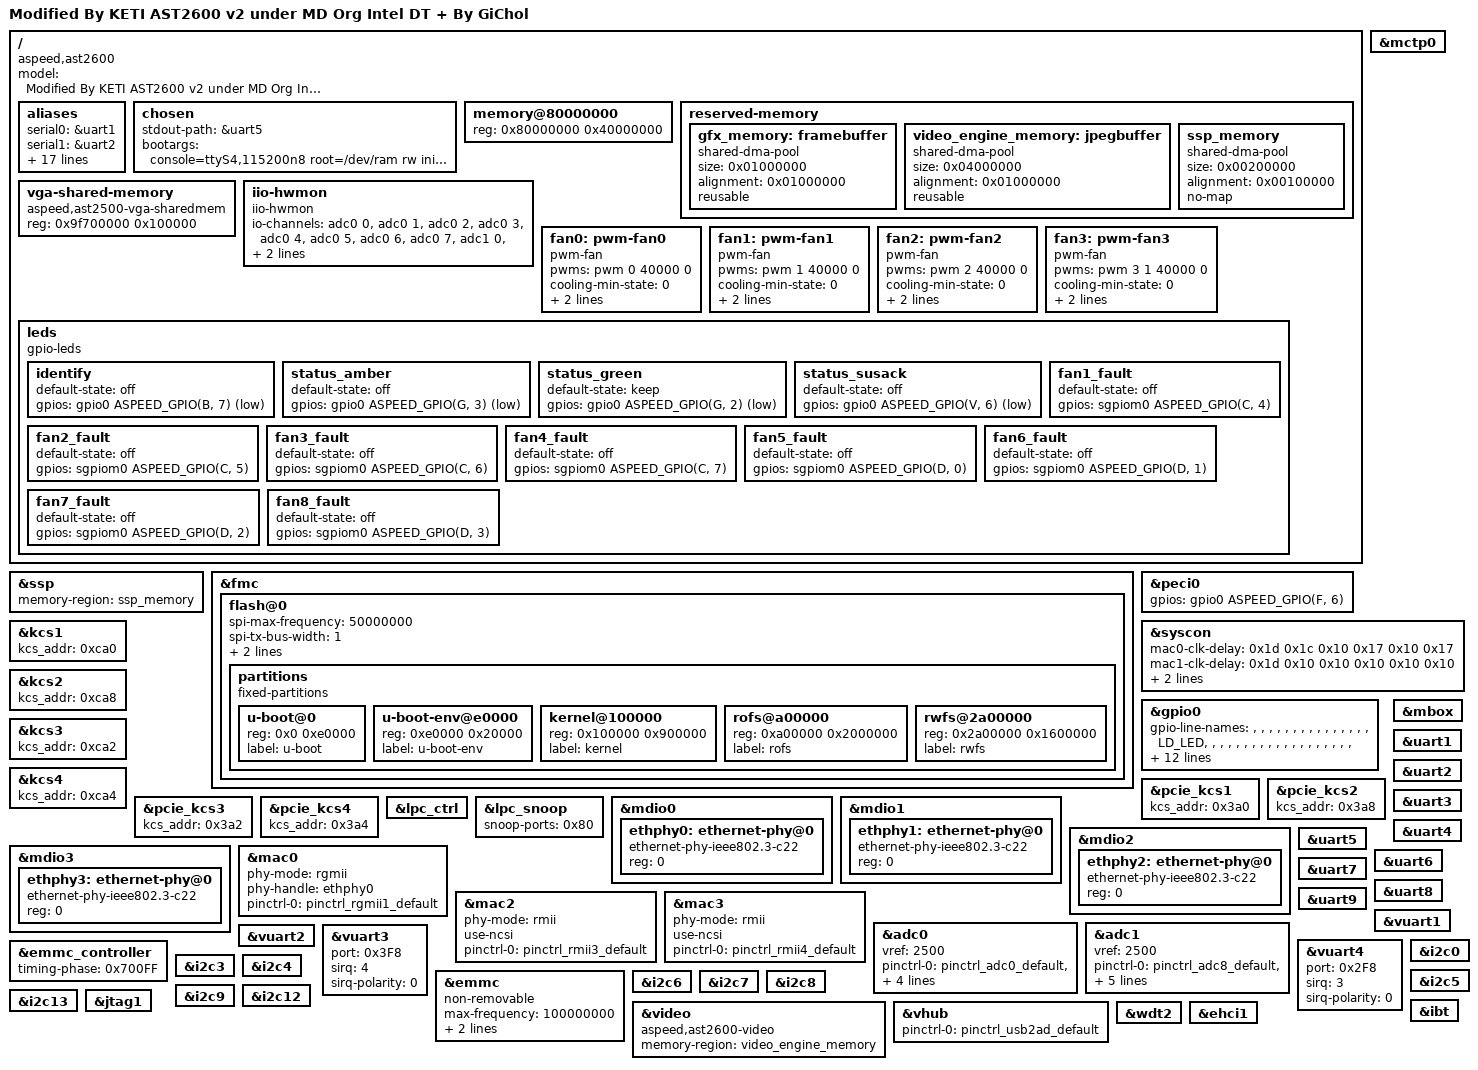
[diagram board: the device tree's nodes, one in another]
// SPDX-License-Identifier: GPL-2.0+
/dts-v1/;

#include "aspeed-g6.dtsi"
#include <dt-bindings/gpio/aspeed-gpio.h>
#include <dt-bindings/i2c/i2c.h>

/ {
   model = "Modified By KETI AST2600 v2 under MD Org Intel DT + By GiChol";
   compatible = "aspeed,ast2600";

   aliases {
      serial0 = &uart1;
                serial1 = &uart2;
                serial2 = &uart3;
                serial3 = &uart4;
                serial4 = &uart5;
                serial5 = &uart6;
                serial6 = &uart7;
                serial7 = &uart8;
                serial8 = &uart9;
                serial9 = &uart10;
                serial10 = &uart11;
                serial11 = &uart12;
                serial12 = &uart13;
                serial13 = &vuart1;
                serial14 = &vuart2;
                serial15 = &vuart3;
                serial16 = &vuart4;
                mctp0 = &mctp0;
                mctp1 = &mctp1;
   };

   chosen {
      stdout-path = &uart5;
      bootargs = "console=ttyS4,115200n8 root=/dev/ram rw init=/linuxrc earlyprintk";
   };

   memory@80000000 {
      device_type = "memory";
      reg = <0x80000000 0x40000000>;
   };

   reserved-memory {
      #address-cells = <1>;
      #size-cells = <1>;
      ranges;

      gfx_memory: framebuffer {
         size = <0x01000000>;
         alignment = <0x01000000>;
         compatible = "shared-dma-pool";
         reusable;
      };

      video_engine_memory: jpegbuffer {
         size = <0x04000000>;
         alignment = <0x01000000>;
         compatible = "shared-dma-pool";
         reusable;
      };
      ssp_memory: ssp_memory {
         size = <0x00200000>;
         alignment = <0x00100000>;
         compatible = "shared-dma-pool";
         no-map;
      };
   };

   vga-shared-memory {
      compatible = "aspeed,ast2500-vga-sharedmem";
      reg = <0x9f700000 0x100000>;
   };

   iio-hwmon {
      compatible = "iio-hwmon";
      io-channels = <&adc0 0>, <&adc0 1>, <&adc0 2>, <&adc0 3>,
         <&adc0 4>, <&adc0 5>, <&adc0 6>, <&adc0 7>,
         <&adc1 0>, <&adc1 1>, <&adc1 2>, <&adc1 3>,
         <&adc1 4>, <&adc1 5>, <&adc1 6>, <&adc1 7>;
   };
        fan0: pwm-fan0 {
                compatible = "pwm-fan";
                pwms = <&pwm 0 40000 0>;        /* Target freq:25 kHz */
                cooling-min-state = <0>;
                cooling-max-state = <3>;
                #cooling-cells = <2>;
                cooling-levels = <0 25 128 255>;
        };

        fan1: pwm-fan1 {
                compatible = "pwm-fan";
                pwms = <&pwm 1 40000 0>;        /* Target freq:25 kHz */
                cooling-min-state = <0>;
                cooling-max-state = <3>;
                #cooling-cells = <2>;
                cooling-levels = <0 15 128 255>;
        };

        fan2: pwm-fan2 {
                compatible = "pwm-fan";
                pwms = <&pwm 2 40000 0>;        /* Target freq:25 kHz */
                cooling-min-state = <0>;
                cooling-max-state = <3>;
                #cooling-cells = <2>;
                cooling-levels = <0 15 128 255>;
        };

        fan3: pwm-fan3 {
                compatible = "pwm-fan";
                pwms = <&pwm 3 1 40000 0>;        /* Target freq:25 kHz */
                cooling-min-state = <0>;
                cooling-max-state = <3>;
                #cooling-cells = <2>;
                cooling-levels = <0 15 128 255>;
        };

        leds {
                compatible = "gpio-leds";

                identify {
                        default-state = "off";
                        gpios = <&gpio0 ASPEED_GPIO(B, 7) GPIO_ACTIVE_LOW>;
                };

                status_amber {
                        default-state = "off";
                        gpios = <&gpio0 ASPEED_GPIO(G, 3) GPIO_ACTIVE_LOW>;
                };

                status_green {
                        default-state = "keep";
                        gpios = <&gpio0 ASPEED_GPIO(G, 2) GPIO_ACTIVE_LOW>;
                };

                status_susack {
                        default-state = "off";
                        gpios = <&gpio0 ASPEED_GPIO(V, 6) GPIO_ACTIVE_LOW>;
                };

                fan1_fault {
                        default-state = "off";
                        gpios = <&sgpiom0 ASPEED_GPIO(C, 4) GPIO_ACTIVE_HIGH>;
                };

                fan2_fault {
                        default-state = "off";
                        gpios = <&sgpiom0 ASPEED_GPIO(C, 5) GPIO_ACTIVE_HIGH>;
                };

                fan3_fault {
                        default-state = "off";
                        gpios = <&sgpiom0 ASPEED_GPIO(C, 6) GPIO_ACTIVE_HIGH>;
                };

                fan4_fault {
                        default-state = "off";
                        gpios = <&sgpiom0 ASPEED_GPIO(C, 7) GPIO_ACTIVE_HIGH>;
                };

                fan5_fault {
                        default-state = "off";
                        gpios = <&sgpiom0 ASPEED_GPIO(D, 0) GPIO_ACTIVE_HIGH>;
                };

                fan6_fault {
                        default-state = "off";
                        gpios = <&sgpiom0 ASPEED_GPIO(D, 1) GPIO_ACTIVE_HIGH>;
                };

                fan7_fault {
                        default-state = "off";
                        gpios = <&sgpiom0 ASPEED_GPIO(D, 2) GPIO_ACTIVE_HIGH>;
                };

                fan8_fault {
                        default-state = "off";
                        gpios = <&sgpiom0 ASPEED_GPIO(D, 3) GPIO_ACTIVE_HIGH>;
                };
        };
};

&ssp {
      memory-region = <&ssp_memory>;
};

&fmc {
   status = "okay";
   flash@0 {
      status = "okay";
      spi-max-frequency = <50000000>;
      spi-tx-bus-width = <1>;
      spi-rx-bus-width = <4>;
      m25p,fast-read;
      partitions {
         compatible = "fixed-partitions";
         #address-cells = <1>;
         #size-cells = <1>;

         u-boot@0 {
            reg = <0x0 0xe0000>;
            label = "u-boot";
         };

         u-boot-env@e0000 {
            reg = <0xe0000 0x20000>; // 128KB
            label = "u-boot-env";
         };

         kernel@100000 {
            reg = <0x100000 0x900000>; // 9MB
            label = "kernel";
         };

         rofs@a00000 {
            reg = <0xa00000 0x2000000>; // 32MB
            label = "rofs";
         };

         rwfs@2a00000 {
            reg = <0x2a00000 0x1600000>; // 22MB
            label = "rwfs";
         };
      };
   };
};
#if 0
&espi_ctrl {
   status = "okay";
   perif,memcyc-enable;
   perif,memcyc-src-addr = <0x98000000>;
   perif,memcyc-size = <0x10000>;
   perif,dma-mode;

   oob,dma-mode;
   oob,dma-tx-desc-num = <0x2>;
   oob,dma-rx-desc-num = <0x8>;

   flash,dma-mode;
   flash,safs-mode = <0x2>;
};
#endif

&mctp0 {
   status = "okay";
};

&peci0 {
   status = "okay";
   gpios = <&gpio0 ASPEED_GPIO(F, 6) 0>;
};

&syscon {
   mac0-clk-delay = <0x1d 0x1c
           0x10 0x17
           0x10 0x17>;
   mac1-clk-delay = <0x1d 0x10
           0x10 0x10
           0x10 0x10>;
   mac2-clk-delay = <0x0a 0x04
           0x08 0x04
           0x08 0x04>;
   mac3-clk-delay = <0x0a 0x04
           0x08 0x04
           0x08 0x04>;
};

&gpio0 {
        //pinctrl-names = "default";
        //pinctrl-0 = <&pinctrl_gpioh_unbiased>;
      status="okay";
        gpio-line-names =
        /*A0-A7*/       "","","","","","","","",//0,1,2,3,4,5,6,7
        /*B0-B7*/       "","","","","","","","LD_LED",//8,9,10,11,12,13,14,15,
        /*C0-C7*/       "","","","","","","","", //16,17,18,19,20,21,22,23,
        /*D0-D7*/       "","","","","","","","", //24,25,26,27,28,29,30,31,
        /*E0-E7*/       "","","","","","","","", //32,33,34,35,36,37,38,39,
        /*F0-F7*/       "","","","","","","LD_BTN","",//40,41,42,43,44,45,46,47,
        /*G0-G7*/       "","","FP_LED_GREEN","FP_LED_AMBER","","","","",
        /*H0-H7*/       "","","","","","","","",
        /*I0-I7*/       "","","","","","PWR_BTN_OUT","","",
        /*J0-J7*/       "","","","","","","","",
        /*K0-K7*/       "","","","","","","","",
        /*L0-L7*/       "","","","","","","","",
        /*M0-M7*/       "","","","","","","","",
        /*N0-N7*/       "","","","","","","","",
        /*O0-O7*/       "","","","","","","","",
        /*P0-P7*/       "FP_RST_BTN_IN","RST_BTN_OUT","PWR_BTN_IN","","","","","",
        /*Q0-Q7*/       "","","","","","","","",//97
        /*R0-R7*/       "","","","","","","","",//105
        /*S0-S7*/       "","","","","","GPIO_BAT","","",//113
        /*T0-T7*/       "","","","","","","","",
        /*U0-U7*/       "","","","","","","","",
        /*V0-V7*/       "","PWR_OK","","","","","","",
        /*W0-W7*/       "","","","","","","","",
        /*X0-X7*/       "","","","","","","","",
        /*Y0-Y7*/       "","","","","","","","",
        /*Z0-Z7*/       "","","","","","","","",
        /*AA0-AA7*/     "","","","","","","","",
        /*AB0-AB7*/     "","","","","","","","",
        /*AC0-AC7*/     "","","","","","","","";
};

&kcs1 {
   kcs_addr = <0xca0>;
   status = "okay";
};

&kcs2 {
   kcs_addr = <0xca8>;
   status = "okay";
};

&kcs3 {
   kcs_addr = <0xca2>;
   status = "okay";
};

&kcs4 {
   kcs_addr = <0xca4>;
   status = "okay";
};

&pcie_kcs1 {
   kcs_addr = <0x3a0>;
   status = "okay";
};

&pcie_kcs2 {
   kcs_addr = <0x3a8>;
   status = "okay";
};

&pcie_kcs3 {
   kcs_addr = <0x3a2>;
   status = "okay";
};

&pcie_kcs4 {
   kcs_addr = <0x3a4>;
   status = "okay";
};

&lpc_ctrl {
        status = "okay";
};

// &lpc {
//         kcs4: kcs4@0 {
//                 compatible = "openbmc,mctp-lpc";
//                 interrupts = <GIC_SPI 141 IRQ_TYPE_LEVEL_HIGH>;
//                 status = "okay";
//         };
// };

#if 1
&lpc_snoop {
   snoop-ports = <0x80>;
   status = "okay";
};
#endif

#if 0
&pcie_snoop {
   snoop-ports = <0x80>;
   status = "okay";
};
#endif

&mbox {
   status = "okay";
};
&mdio0 {
	status = "okay";

	ethphy0: ethernet-phy@0 {
		compatible = "ethernet-phy-ieee802.3-c22";
		reg = <0>;
	};
};

&mdio1 {
	status = "okay";
	ethphy1: ethernet-phy@0 {
		compatible = "ethernet-phy-ieee802.3-c22";
		reg = <0>;
	};
};

&mdio2 {
	status = "okay";
	ethphy2: ethernet-phy@0 {
		compatible = "ethernet-phy-ieee802.3-c22";
		reg = <0>;
	};
};

&mdio3 {
	status = "okay";

	ethphy3: ethernet-phy@0 {
		compatible = "ethernet-phy-ieee802.3-c22";
		reg = <0>;
	};
};

&mac0 {
	status = "okay";

	phy-mode = "rgmii";
	phy-handle = <&ethphy0>;

	pinctrl-names = "default";
	pinctrl-0 = <&pinctrl_rgmii1_default>;
};

&mac2 {
	status = "okay";

	phy-mode = "rmii";
	use-ncsi;

	pinctrl-names = "default";
	pinctrl-0 = <&pinctrl_rmii3_default>;
};

&mac3 {
	status = "okay";

	phy-mode = "rmii";
	use-ncsi;

	pinctrl-names = "default";
	pinctrl-0 = <&pinctrl_rmii4_default>;
};

&adc0 {
   vref = <2500>;
   status = "okay";

   pinctrl-names = "default";
   pinctrl-0 = <&pinctrl_adc0_default &pinctrl_adc1_default
      &pinctrl_adc2_default &pinctrl_adc3_default
      &pinctrl_adc4_default &pinctrl_adc5_default
      &pinctrl_adc6_default &pinctrl_adc7_default>;
};

&adc1 {
   vref = <2500>;
   status = "okay";

   pinctrl-names = "default";
   pinctrl-0 = <&pinctrl_adc8_default &pinctrl_adc9_default
      &pinctrl_adc10_default &pinctrl_adc11_default
      &pinctrl_adc12_default &pinctrl_adc13_default
      &pinctrl_adc14_default &pinctrl_adc15_default>;
};

&uart1 {
   status = "okay";
};

&uart2 {
   status = "okay";
};

&uart3 {
   status = "okay";
};

&uart4 {
   status = "okay";
};

&uart5 {
   status = "okay";
};

&uart6 {
   status = "okay";
};

&uart7 {
   status = "okay";
};

&uart8 {
   status = "okay";
};

&uart9 {
   status = "okay";
};

#if 1
&vuart1 {
   status = "okay";
};

&vuart2 {
   status = "okay";
};
#endif

&vuart3 {
   port = <0x3F8>;
   sirq = <4>;
   sirq-polarity = <0>;
   status = "okay";
};

&vuart4 {
   port = <0x2F8>;
   sirq = <3>;
   sirq-polarity = <0>;
   status = "okay";
};

&emmc_controller{
   status = "okay";
   timing-phase = <0x700FF>;
};

&emmc {
   status = "okay";

   non-removable;
   max-frequency = <100000000>;
   sdhci-drive-type = /bits/ 8 <3>;
   bus-width = <4>;
};

//SMB_CHASSENSOR
&i2c0 {
   status = "okay";
};

//SMB_PCIE_S1
&i2c3 {
   status = "okay";
};

//SMB_HSBP_STBY
&i2c4 {
   status = "okay";
};

//SMB_SMLINK0
&i2c5 {
   status = "okay";
};

//SMB_TEMPSENSOR
&i2c6 {
   status = "okay";

   // //rear right ambient
   // tmp75@4e {
   //    compatible = "ti,tmp75";
   //    reg = <0x4e>;
   // };

   // //CPU ambient
   // tmp75@4f {
   //    compatible = "ti,tmp75";
   //    reg = <0x4f>;
   // };

   // //front right ambient
   // tmp75@49 {
   //    compatible = "ti,tmp75";
   //    reg = <0x49>;
   // };

   // //PCIE ambient
   // tmp75@4a {
   //    compatible = "ti,tmp75";
   //    reg = <0x4a>;
   // };

   // //front left ambient
   // tmp75@48 {
   //    compatible = "ti,tmp75";
   //    reg = <0x48>;
   // };
};

//SMB_PMBUS_SML1
&i2c7 {
   status = "okay";
};

//SMB_PCIE_STBY
&i2c8 {
   status = "okay";
};

//SMB_HOST_STBY
&i2c9 {
   status = "okay";
};

//CMM
&i2c12 {
   status = "okay";
};

//PMBUS
&i2c13 {
   status = "okay";
};

&video {
   status = "okay";
   compatible = "aspeed,ast2600-video";
   memory-region = <&video_engine_memory>;
};

&vhub {
   status = "okay";
   pinctrl-names = "default";
#if 1
   pinctrl-0 = <&pinctrl_usb2ad_default>;
#else
   pinctrl-0 = <&pinctrl_usb2adp_default>;
#endif
};

&jtag1 {
   status = "okay";
};

&wdt2 {
   status = "okay";
};

#if 1
&ibt {
   status = "okay";
};
#endif

#if 0
&pcie_ibt {
   status = "okay";
};
#endif 

#if 0
&pcie0 {
   status = "okay";
};

&pcie1 {
   status = "okay";
};
#endif

#if 0
&ehci0 {
   status = "okay";
};
#endif

&ehci1 {
   status = "okay";
};
